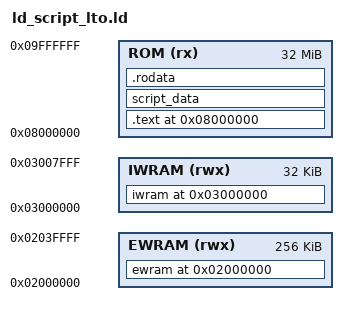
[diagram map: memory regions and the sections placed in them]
ENTRY(Start)

gNumMusicPlayers = 4;
gMaxLines = 0;
gInitialMainCB2 = CB2_InitCopyrightScreenAfterBootup;

MEMORY
{
    EWRAM (rwx) : ORIGIN = 0x2000000, LENGTH = 256K
    IWRAM (rwx) : ORIGIN = 0x3000000, LENGTH = 32K
    ROM    (rx) : ORIGIN = 0x8000000, LENGTH = 32M
}

SECTIONS
{
    ewram 0x2000000 (NOLOAD) :
    ALIGN(4)
    {
        *(ewram_data);
    } > EWRAM

    iwram 0x3000000 (NOLOAD) :
    ALIGN(4)
    {
        *(.bss*);
        *(common_data);
        *(COMMON);
    } > IWRAM

    . = 0x8000000;

    .text :
    ALIGN(4)
    {
        src/rom_header.o(.text*);
        src/rom_header_gf.o(.text*);
        src/rom_header_rhh.o(.text*);
        src/crt0.o(.text);
        *libagbsyscall.a:*.o(.text*);
        *libgcc.a:*.o(.text*);
        *libc.a:*.o(.text*);
        *libnosys.a:*.o(.text*);
        asm/*.o(.text*);
        *(.text*);
        *(.eh_frame);
    } > ROM =0

    script_data :
    ALIGN(4)
    {
        KEEP(data/*.o(script_data));
    } > ROM =0

    .rodata :
    ALIGN(4)
    {
        *(.rodata*);
        *libgcc.a:*.o(.rodata*);
        *libc.a:*.o(.rodata*);
        *libc.a:*.o(.data*);
        sound/songs/*.o(.rodata);
    } > ROM =0

    __rom_end = .;

    .debug          0 : { *(.debug) }
    .line           0 : { *(.line) }
    .debug_srcinfo  0 : { *(.debug_srcinfo) }
    .debug_sfnames  0 : { *(.debug_sfnames) }
    .debug_aranges  0 : { *(.debug_aranges) }
    .debug_pubnames 0 : { *(.debug_pubnames) }
    .debug_info     0 : { *(.debug_info .gnu.linkonce.wi.*) }
    .debug_abbrev   0 : { *(.debug_abbrev) }
    .debug_line     0 : { *(.debug_line) }
    .debug_frame    0 : { *(.debug_frame) }
    .debug_str      0 : { *(.debug_str) }
    .debug_loc      0 : { *(.debug_loc) }
    .debug_macinfo  0 : { *(.debug_macinfo) }
    .debug_line_str 0 : { *(.debug_line_str) }

    /DISCARD/ :
    {
        *(*);
    }
}
